# G32R501 register map
Vendor: Geehy Semiconductor Co., Ltd.; Series: G32R5; File version: 1.0
CPU: CM55 r0p1, little endian, MPU, FPU, double-precision FPU, DSP, VTOR, 4 interrupt priority bits
Registers are 32-bit, read-write, reset 0x0 unless marked. A register's access mark holds for its fields unless they carry their own. Offsets are from the block's base; [hi:lo] are bit positions; {n}, {i} and the like mark numbered series.

## ADCA — Analog-to-digital converter
Base 0x40020000
Same registers: ADCB 0x40020400, ADCC 0x40020800
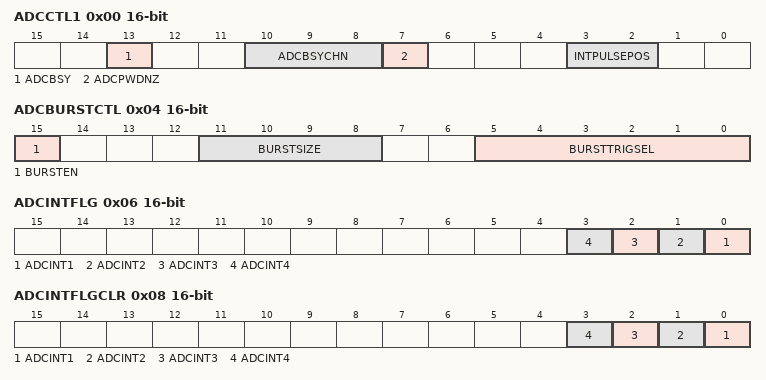
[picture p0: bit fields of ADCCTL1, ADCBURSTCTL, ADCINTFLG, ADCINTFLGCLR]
0x00 ADCCTL1 16-bit access per field — ADC Control 1 Register
  [13] ADCBSY ro — ADC Busy
  [10:8] ADCBSYCHN ro — ADC Busy Channel
  [7] ADCPWDNZ rw — ADC Power Down
  [3:2] INTPULSEPOS rw — ADC Interrupt Pulse Position
0x02 ADCCTL2 16-bit — ADC Control 2 Register
  [3:0] PRESCALE — ADC Clock Prescaler
0x04 ADCBURSTCTL 16-bit — ADC Burst Control Register
  [15] BURSTEN — SOC Burst Mode Enable
  [11:8] BURSTSIZE — SOC Burst Size Select
  [5:0] BURSTTRIGSEL — SOC Burst Trigger Source Select
0x06 ADCINTFLG 16-bit ro — ADC Interrupt Flag Register
  [n-1] ADCINT{n} (n=1..4) — ADC Interrupt {n} Flag
0x08 ADCINTFLGCLR 16-bit — ADC Interrupt Flag Clear Register
  [n-1] ADCINT{n} (n=1..4) — ADC Interrupt {n} Flag Clear
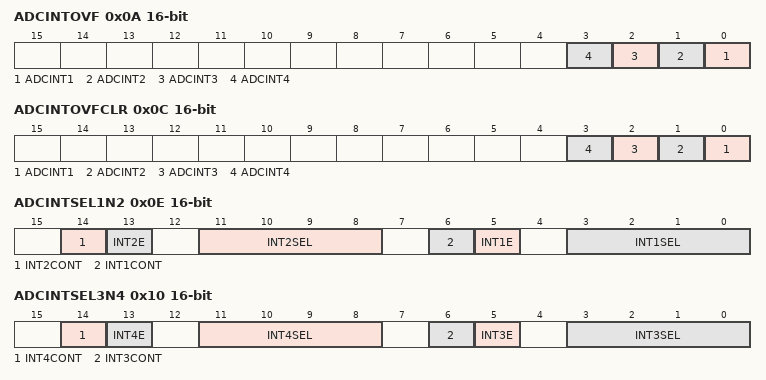
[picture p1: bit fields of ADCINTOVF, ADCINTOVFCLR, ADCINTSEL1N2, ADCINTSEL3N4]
0x0A ADCINTOVF 16-bit ro — ADC Interrupt Overflow Register
  [n-1] ADCINT{n} (n=1..4) — ADC Interrupt {n} Overflow Flags
0x0C ADCINTOVFCLR 16-bit — ADC Interrupt Overflow Clear Register
  [n-1] ADCINT{n} (n=1..4) — ADC Interrupt {n} Overflow Clear Bits
0x0E ADCINTSEL1N2 16-bit — ADC Interrupt 1 and 2 Selection Register
  [14] INT2CONT — ADCINT2 Continue to Interrupt Mode
  [13] INT2E — ADCINT2 Interrupt Enable
  [11:8] INT2SEL — ADCINT2 EOC Source Select
  [6] INT1CONT — ADCINT1 Continue to Interrupt Mode
  [5] INT1E — ADCINT1 Interrupt Enable
  [3:0] INT1SEL — ADCINT1 EOC Source Select
0x10 ADCINTSEL3N4 16-bit — ADC Interrupt 3 and 4 Selection Register
  [14] INT4CONT — ADCINT4 Continue to Interrupt Mode
  [13] INT4E — ADCINT4 Interrupt Enable
  [11:8] INT4SEL — ADCINT4 EOC Source Select
  [6] INT3CONT — ADCINT3 Continue to Interrupt Mode
  [5] INT3E — ADCINT3 Interrupt Enable
  [3:0] INT3SEL — ADCINT3 EOC Source Select
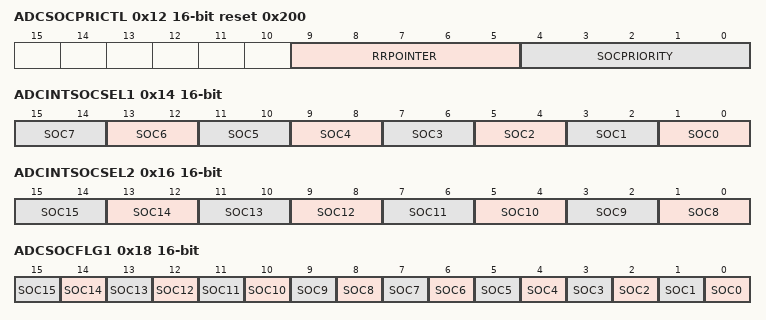
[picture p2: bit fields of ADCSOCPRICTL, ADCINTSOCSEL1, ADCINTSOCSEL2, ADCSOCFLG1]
0x12 ADCSOCPRICTL 16-bit access per field reset 0x200 — ADC SOC Priority Control Register
  [9:5] RRPOINTER ro — Round Robin Pointer
  [4:0] SOCPRIORITY rw
0x14 ADCINTSOCSEL1 16-bit — ADC Interrupt SOC Selection 1 Register
  [2n+1:2n] SOC{n} (n=0..7) — SOC{n} ADC Interrupt Trigger Select
0x16 ADCINTSOCSEL2 16-bit — ADC Interrupt SOC Selection 2 Register
  [2n-15:2n-16] SOC{n} (n=8..15) — SOC{n} ADC Interrupt Trigger Select
0x18 ADCSOCFLG1 16-bit ro — ADC SOC Flag 1 Register
  [n] SOC{n} (n=0..15) — SOC{n} Start of Conversion Flag
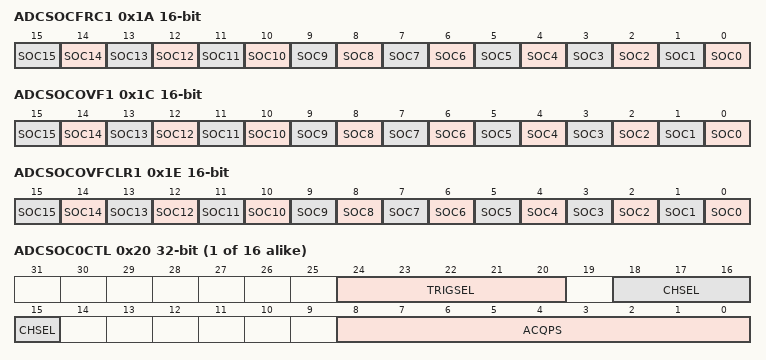
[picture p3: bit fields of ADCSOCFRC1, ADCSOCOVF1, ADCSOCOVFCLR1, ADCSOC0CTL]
0x1A ADCSOCFRC1 16-bit — ADC SOC Force 1 Register
  [n] SOC{n} (n=0..15) — SOC{n} Force Start of Conversion Bit
0x1C ADCSOCOVF1 16-bit ro — ADC SOC Overflow Clear 1 Register
  [n] SOC{n} (n=0..15) — SOC{n} Start of Conversion Overflow Flag
0x1E ADCSOCOVFCLR1 16-bit — ADC SOC Overflow Clear 1 Register
  [n] SOC{n} (n=0..15) — SOC{n} Clear Start of Conversion Overflow Bit
{0x20+4i} ADCSOC{i}CTL (i=0..15) — ADC SOC{i} Control Register
  [24:20] TRIGSEL — SOC{i} Trigger Source Select
  [18:15] CHSEL — SOC{i} Channel Select
  [8:0] ACQPS — SOC{i} Acquisition Prescale
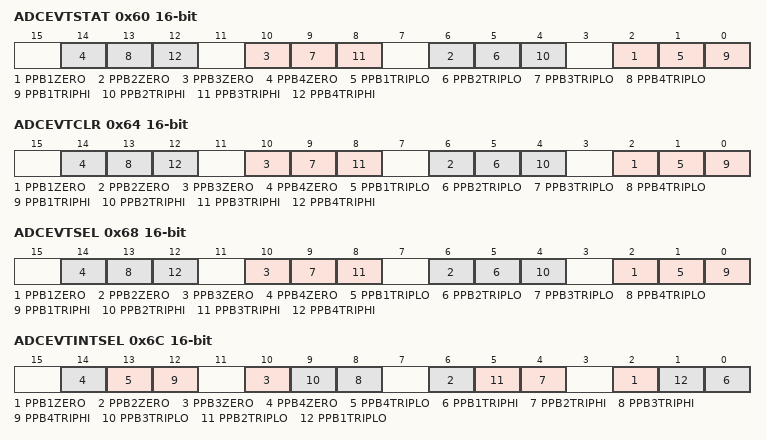
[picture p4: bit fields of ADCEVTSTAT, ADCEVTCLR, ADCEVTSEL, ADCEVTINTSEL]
0x60 ADCEVTSTAT 16-bit ro — ADC Event Status Register
  [4n-2] PPB{n}ZERO (n=1..4) — Post Processing Block {n} Zero Crossing Flag
  [4n-3] PPB{n}TRIPLO (n=1..4) — Post Processing Block {n} Trip Low Flag
  [4n-4] PPB{n}TRIPHI (n=1..4) — Post Processing Block {n} Trip High Flag
0x64 ADCEVTCLR 16-bit — ADC Event Clear Register
  [4n-2] PPB{n}ZERO (n=1..4) — Post Processing Block {n} Zero Crossing Clear
  [4n-3] PPB{n}TRIPLO (n=1..4) — Post Processing Block {n} Trip Low Clear
  [4n-4] PPB{n}TRIPHI (n=1..4) — Post Processing Block {n} Trip High Clear
0x68 ADCEVTSEL 16-bit — ADC Event Selection Register
  [4n-2] PPB{n}ZERO (n=1..4) — Post Processing Block {n} Zero Crossing Event Enable
  [4n-3] PPB{n}TRIPLO (n=1..4) — Post Processing Block {n} Trip Low Event Enable
  [4n-4] PPB{n}TRIPHI (n=1..4) — Post Processing Block {n} Trip High Event Enable
0x6C ADCEVTINTSEL 16-bit — ADC Event Interrupt Selection Register
  [4n-2] PPB{n}ZERO (n=1..4) — Post Processing Block {n} Zero Crossing Interrupt Enable
  [13] PPB4TRIPLO — 13 Post Processing Block 4 Trip Low Interrupt Enable
  [4n-4] PPB{n}TRIPHI (n=1..4) — Post Processing Block {n} Trip High Interrupt Enable
  [9] PPB3TRIPLO — Post Processing Block 3 Trip Low Interrupt Enable
  [5] PPB2TRIPLO — Post Processing Block 2 Trip Low Interrupt Enable
  [1] PPB1TRIPLO — Post Processing Block 1 Trip Low Interrupt Enable
0x70 ADCOSDETECT 16-bit — ADC Open and Shorts Detect Register
  [2:0] DETECTCFG — ADC Opens and Shorts Detect Configuration
0x72 ADCCOUNTER 16-bit ro
  [11:0] FREECOUNT — ADC Free Running Counter Value
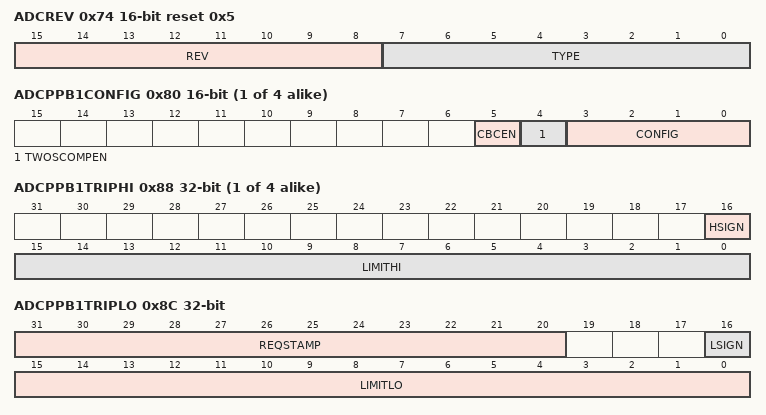
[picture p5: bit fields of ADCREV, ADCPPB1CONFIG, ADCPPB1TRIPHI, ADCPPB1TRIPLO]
0x74 ADCREV 16-bit ro reset 0x5 — ADC Revision Register
  [15:8] REV — ADC Revision
  [7:0] TYPE — ADC Type
0x76 ADCOFFTRIM 16-bit — ADC Offset Trim Register
  [7:0] OFFTRIM — ADC Offset Trim
{0x70+0x10*i} ADCPPB{i}CONFIG 16-bit (i=1..4)
  [5] CBCEN — Cycle By Cycle Enable
  [4] TWOSCOMPEN — ADC Post Processing Block {i} Two's Complement Enable
  [3:0] CONFIG — ADC Post Processing Block {i} Configuration
{0x72+0x10*i} ADCPPB{i}STAMP 16-bit ro (i=1..4) — ADC PPB{i} Sample Delay Time Stamp Register
  [11:0] DLYSTAMP — ADC Post Processing Block {i} Delay Time Stamp
0x84 ADCPPB1OFFCAL 16-bit — ADC PPB1 Offset Calibration Register
  [9:0] OFFCAL — ADC Post Processing Block Offset Correction
{0x76+0x10*i} ADCPPB{i}OFFREF 16-bit (i=1..4) — ADC PPB{i} Offset Reference Register
  [15:0] OFFREF — ADC Post Processing Block {i} Offset Correction
{0x78+0x10*i} ADCPPB{i}TRIPHI (i=1..4) — ADC PPB{i} Trip High Register
  [16] HSIGN — High Limit Sign Bit
  [15:0] LIMITHI — ADC Post Processing Block {i} Trip High Limit
0x8C ADCPPB1TRIPLO access per field — ADC PPB1 Trip Low/Trigger Time Stamp Register
  [31:20] REQSTAMP ro — ADC Post Processing Block 1 Request Time Stamp
  [16] LSIGN rw — Low Limit Sign Bit
  [15:0] LIMITLO rw — ADC Post Processing Block 1 Trip Low Limit
0x94 ADCPPB2OFFCAL 16-bit — ADC PPB2 Sample Delay Time Stamp Register
  [9:0] OFFCAL — ADC Post Processing Block Offset Correction
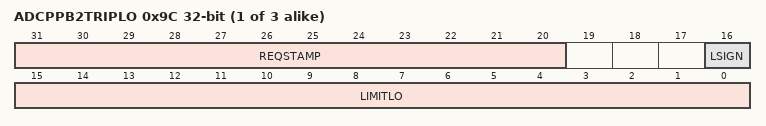
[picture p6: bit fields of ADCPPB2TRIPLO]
{0x7C+0x10*i} ADCPPB{i}TRIPLO (i=2..4) — ADC PPB{i} Trip Low/Trigger Time Stamp Register
  [31:20] REQSTAMP ro — ADC Post Processing Block {i} Request Time Stamp
  [16] LSIGN — Low Limit Sign Bit
  [15:0] LIMITLO — ADC Post Processing Block {i} Trip Low Limit
0xA4 ADCPPB3OFFCAL 16-bit — ADC PPB3 Offset Calibration Register
  [9:0] OFFCAL — ADC Post Processing Block Offset Correction
0xB4 ADCPPB4OFFCAL 16-bit — ADC PPB4 Offset Calibration Register
  [9:0] OFFCAL — ADC Post Processing Block Offset Correction
0xDE ADCINTCYCLE 16-bit — ADC Early Interrupt Generation Cycle
  [15:0] DELAY — ADC Early Interrupt Generation Cycle Delay
0xE4 ADCLINETRIM2 — ADC Linearity Trim 2 Register
  [31:0] INLTRIM63TO32 — ADC Linearity Trim Bits 63-32
0xE8 ADCLINETRIM3 — ADC Linearity Trim 3 Register
  [31:0] INLTRIM95TO64 — ADC Linearity Trim Bits 95-64
